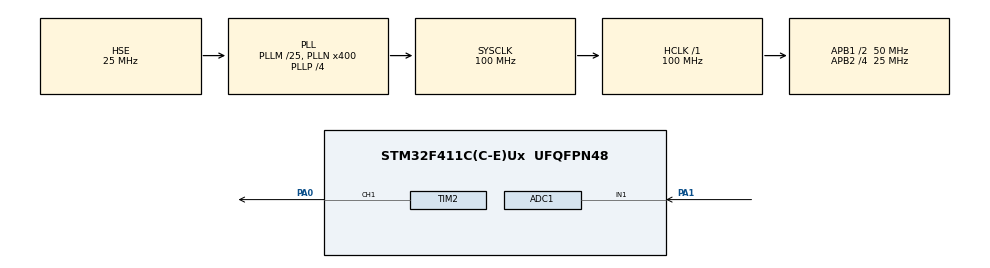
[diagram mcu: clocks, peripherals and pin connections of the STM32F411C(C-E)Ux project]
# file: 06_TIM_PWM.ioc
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ADC1.Channel-0\#ChannelRegularConversion=ADC_CHANNEL_1
ADC1.NbrOfConversionFlag=1
ADC1.Rank-0\#ChannelRegularConversion=1
ADC1.SamplingTime-0\#ChannelRegularConversion=ADC_SAMPLETIME_3CYCLES
ADC1.master=1
Mcu.Family=STM32F4
Mcu.Name=STM32F411C(C-E)Ux
Mcu.Package=UFQFPN48
NVIC.PriorityGroup=NVIC_PRIORITYGROUP_4
PA0-WKUP.Signal=S_TIM2_CH1_ETR
PA1.Signal=ADCx_IN1
PA13.Mode=Serial_Wire
PA13.Signal=SYS_JTMS-SWDIO
PA14.Mode=Serial_Wire
PA14.Signal=SYS_JTCK-SWCLK
PH0\ -\ OSC_IN.Mode=HSE-External-Oscillator
PH0\ -\ OSC_IN.Signal=RCC_OSC_IN
PH1\ -\ OSC_OUT.Mode=HSE-External-Oscillator
PH1\ -\ OSC_OUT.Signal=RCC_OSC_OUT
ProjectManager.HeapSize=0x200
ProjectManager.StackSize=0x400
ProjectManager.TargetToolchain=Makefile
RCC.48MHZClocksFreq_Value=100000000
RCC.AHBFreq_Value=100000000
RCC.APB1CLKDivider=RCC_HCLK_DIV2
RCC.APB1Freq_Value=50000000
RCC.APB1TimFreq_Value=100000000
RCC.APB2CLKDivider=RCC_HCLK_DIV4
RCC.APB2Freq_Value=25000000
RCC.APB2TimFreq_Value=50000000
RCC.CortexFreq_Value=100000000
RCC.HCLKFreq_Value=100000000
RCC.HSE_VALUE=25000000
RCC.HSI_VALUE=16000000
RCC.LSE_VALUE=32768
RCC.PLLM=25
RCC.PLLN=400
RCC.PLLP=RCC_PLLP_DIV4
RCC.PLLSourceVirtual=RCC_PLLSOURCE_HSE
RCC.SYSCLKFreq_VALUE=100000000
RCC.SYSCLKSource=RCC_SYSCLKSOURCE_PLLCLK
RCC.VCOOutputFreq_Value=400000000
SH.ADCx_IN1.0=ADC1_IN1,IN1
SH.S_TIM2_CH1_ETR.0=TIM2_CH1,PWM Generation1 CH1
TIM2.AutoReloadPreload=TIM_AUTORELOAD_PRELOAD_ENABLE
TIM2.Channel-PWM\ Generation1\ CH1=TIM_CHANNEL_1
TIM2.Period=999
TIM2.Prescaler=4
VP_TIM2_VS_ClockSourceINT.Mode=Internal
board=custom

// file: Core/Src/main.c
/* USER CODE BEGIN Header */
/**
  ******************************************************************************
  * @file           : main.c
  * @brief          : Main program body
  ******************************************************************************
  * @attention
  *
  * Copyright (c) 2026 STMicroelectronics.
  * All rights reserved.
  *
  * This software is licensed under terms that can be found in the LICENSE file
  * in the root directory of this software component.
  * If no LICENSE file comes with this software, it is provided AS-IS.
  *
  ******************************************************************************
  */
/* USER CODE END Header */
#include "main.h"
#include "adc.h"
#include "tim.h"
#include "gpio.h"

/* USER CODE BEGIN PV */
typedef struct{
  uint16_t current_speed;  // Motorun şu anki hızı (0-999)
  uint16_t target_speed;    // Ulaşılmak istenen hedef hız (0-999)
  uint32_t last_tick;       // Son hızın güncellenmesinin zamanı (ms)
  uint32_t step_interval_ms;  // kaç saniyede bir hız adımı atılacak
}MotorController_t;

MotorController_t motor ={
  .current_speed = 0,
  .target_speed = 0,
  .last_tick = 0,
  .step_interval_ms = 10
};
/* USER CODE END PV */

void SystemClock_Config(void);

/* USER CODE BEGIN 0 */
void Motor_Set_Speed(uint16_t duty){
  if(duty > 999) duty = 999;     // ARR sınırını asla aşma
  __HAL_TIM_SET_COMPARE(&htim2, TIM_CHANNEL_1, duty);
}
/* USER CODE END 0 */

int main(void)
{

  /* MCU Configuration--------------------------------------------------------*/

  /* Reset of all peripherals, Initializes the Flash interface and the Systick. */
  HAL_Init();

  /* Configure the system clock */
  SystemClock_Config();

  /* Initialize all configured peripherals */
  MX_GPIO_Init();
  MX_ADC1_Init();
  MX_TIM2_Init();
  /* USER CODE BEGIN 2 */
  HAL_TIM_PWM_Start(&htim2, TIM_CHANNEL_1);
  Motor_Set_Speed(0);
  /* USER CODE END 2 */

  /* Infinite loop */
  /* USER CODE BEGIN WHILE */
  while (1)
  {
    HAL_ADC_Start(&hadc1);
  HAL_ADC_PollForConversion(&hadc1, HAL_MAX_DELAY);
  uint16_t adc_raw = HAL_ADC_GetValue(&hadc1);

  motor.target_speed = (adc_raw * 999) / 4095;

  uint32_t now = HAL_GetTick();

if (now - motor.last_tick >= motor.step_interval_ms) {
    motor.last_tick = now;

    if (motor.current_speed < motor.target_speed) {
        if (motor.target_speed - motor.current_speed < 5)
            motor.current_speed = motor.target_speed;
        else
            motor.current_speed += 5;

    } else if (motor.current_speed > motor.target_speed) {
        if (motor.current_speed - motor.target_speed < 5)
            motor.current_speed = motor.target_speed;
        else
            motor.current_speed -= 5;
    }

    Motor_Set_Speed(motor.current_speed);
}
    /* USER CODE END WHILE */

  }
}

void SystemClock_Config(void)
{
  RCC_OscInitTypeDef RCC_OscInitStruct = {0};
  RCC_ClkInitTypeDef RCC_ClkInitStruct = {0};

  /** Configure the main internal regulator output voltage
  */
  __HAL_RCC_PWR_CLK_ENABLE();
  __HAL_PWR_VOLTAGESCALING_CONFIG(PWR_REGULATOR_VOLTAGE_SCALE1);

  /** Initializes the RCC Oscillators according to the specified parameters
  * in the RCC_OscInitTypeDef structure.
  */
  RCC_OscInitStruct.OscillatorType = RCC_OSCILLATORTYPE_HSE;
  RCC_OscInitStruct.HSEState = RCC_HSE_ON;
  RCC_OscInitStruct.PLL.PLLState = RCC_PLL_ON;
  RCC_OscInitStruct.PLL.PLLSource = RCC_PLLSOURCE_HSE;
  RCC_OscInitStruct.PLL.PLLM = 25;
  RCC_OscInitStruct.PLL.PLLN = 400;
  RCC_OscInitStruct.PLL.PLLP = RCC_PLLP_DIV4;
  RCC_OscInitStruct.PLL.PLLQ = 4;
  if (HAL_RCC_OscConfig(&RCC_OscInitStruct) != HAL_OK)
  {
    Error_Handler();
  }

  /** Initializes the CPU, AHB and APB buses clocks
  */
  RCC_ClkInitStruct.ClockType = RCC_CLOCKTYPE_HCLK|RCC_CLOCKTYPE_SYSCLK
                              |RCC_CLOCKTYPE_PCLK1|RCC_CLOCKTYPE_PCLK2;
  RCC_ClkInitStruct.SYSCLKSource = RCC_SYSCLKSOURCE_PLLCLK;
  RCC_ClkInitStruct.AHBCLKDivider = RCC_SYSCLK_DIV1;
  RCC_ClkInitStruct.APB1CLKDivider = RCC_HCLK_DIV2;
  RCC_ClkInitStruct.APB2CLKDivider = RCC_HCLK_DIV4;

  if (HAL_RCC_ClockConfig(&RCC_ClkInitStruct, FLASH_LATENCY_3) != HAL_OK)
  {
    Error_Handler();
  }
}

void Error_Handler(void)
{
  __disable_irq();
  while (1)
  {
  }
}
